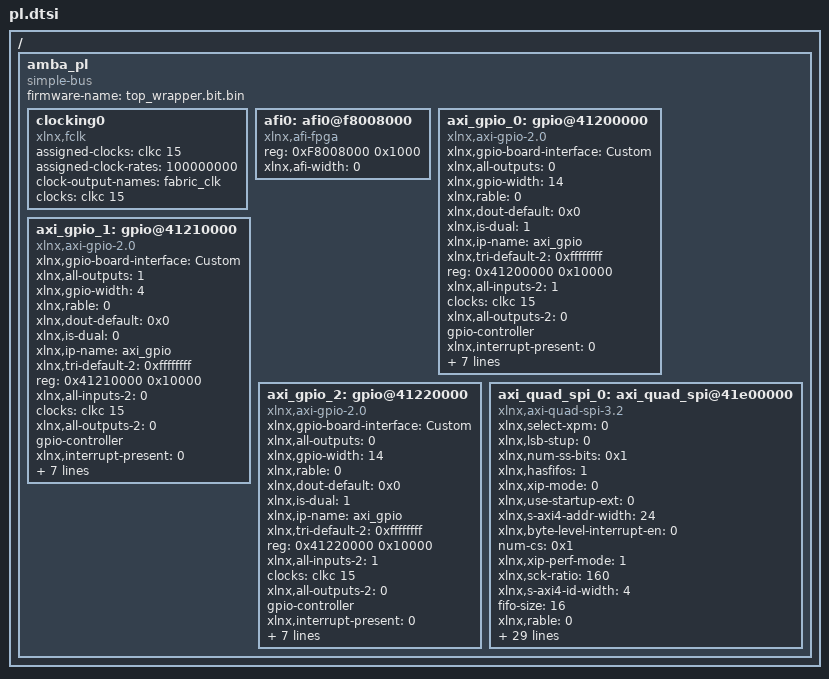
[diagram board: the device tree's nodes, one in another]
/ {
	amba_pl: amba_pl {
		ranges;
		compatible = "simple-bus";
		#address-cells = <1>;
		#size-cells = <1>;
		firmware-name = "top_wrapper.bit.bin";
		clocking0: clocking0 {
			compatible = "xlnx,fclk";
			assigned-clocks = <&clkc 15>;
			assigned-clock-rates = <100000000>;
			#clock-cells = <0>;
			clock-output-names = "fabric_clk";
			clocks = <&clkc 15>;
		};
		afi0: afi0@f8008000 {
			status = "okay";
			compatible = "xlnx,afi-fpga";
			#address-cells = <1>;
			reg = <0xF8008000 0x1000>;
			#size-cells = <0>;
			xlnx,afi-width = <0>;
		};
		axi_gpio_0: gpio@41200000 {
			xlnx,gpio-board-interface = "Custom";
			compatible = "xlnx,axi-gpio-2.0" , "xlnx,xps-gpio-1.00.a";
			xlnx,all-outputs = <0>;
			#gpio-cells = <2>;
			xlnx,gpio-width = <14>;
			xlnx,rable = <0>;
			xlnx,dout-default = <0x0>;
			xlnx,is-dual = <1>;
			xlnx,ip-name = "axi_gpio";
			xlnx,tri-default-2 = <0xffffffff>;
			reg = <0x41200000 0x10000>;
			xlnx,all-inputs-2 = <1>;
			clocks = <&clkc 15>;
			xlnx,all-outputs-2 = <0>;
			gpio-controller;
			xlnx,interrupt-present = <0>;
			xlnx,gpio2-board-interface = "Custom";
			xlnx,edk-iptype = "PERIPHERAL";
			xlnx,dout-default-2 = <0x0>;
			status = "okay";
			xlnx,gpio2-width = <14>;
			clock-names = "s_axi_aclk";
			xlnx,tri-default = <0xffffffff>;
			xlnx,name = "axi_gpio_0";
			xlnx,all-inputs = <1>;
		};
		axi_gpio_1: gpio@41210000 {
			xlnx,gpio-board-interface = "Custom";
			compatible = "xlnx,axi-gpio-2.0" , "xlnx,xps-gpio-1.00.a";
			xlnx,all-outputs = <1>;
			#gpio-cells = <2>;
			xlnx,gpio-width = <4>;
			xlnx,rable = <0>;
			xlnx,dout-default = <0x0>;
			xlnx,is-dual = <0>;
			xlnx,ip-name = "axi_gpio";
			xlnx,tri-default-2 = <0xffffffff>;
			reg = <0x41210000 0x10000>;
			xlnx,all-inputs-2 = <0>;
			clocks = <&clkc 15>;
			xlnx,all-outputs-2 = <0>;
			gpio-controller;
			xlnx,interrupt-present = <0>;
			xlnx,gpio2-board-interface = "Custom";
			xlnx,edk-iptype = "PERIPHERAL";
			xlnx,dout-default-2 = <0x0>;
			status = "okay";
			xlnx,gpio2-width = <32>;
			clock-names = "s_axi_aclk";
			xlnx,tri-default = <0xffffffff>;
			xlnx,name = "axi_gpio_1";
			xlnx,all-inputs = <0>;
		};
		axi_gpio_2: gpio@41220000 {
			xlnx,gpio-board-interface = "Custom";
			compatible = "xlnx,axi-gpio-2.0" , "xlnx,xps-gpio-1.00.a";
			xlnx,all-outputs = <0>;
			#gpio-cells = <2>;
			xlnx,gpio-width = <14>;
			xlnx,rable = <0>;
			xlnx,dout-default = <0x0>;
			xlnx,is-dual = <1>;
			xlnx,ip-name = "axi_gpio";
			xlnx,tri-default-2 = <0xffffffff>;
			reg = <0x41220000 0x10000>;
			xlnx,all-inputs-2 = <1>;
			clocks = <&clkc 15>;
			xlnx,all-outputs-2 = <0>;
			gpio-controller;
			xlnx,interrupt-present = <0>;
			xlnx,gpio2-board-interface = "Custom";
			xlnx,edk-iptype = "PERIPHERAL";
			xlnx,dout-default-2 = <0x0>;
			status = "okay";
			xlnx,gpio2-width = <14>;
			clock-names = "s_axi_aclk";
			xlnx,tri-default = <0xffffffff>;
			xlnx,name = "axi_gpio_2";
			xlnx,all-inputs = <1>;
		};
		axi_quad_spi_0: axi_quad_spi@41e00000 {
			xlnx,select-xpm = <0>;
			compatible = "xlnx,axi-quad-spi-3.2" , "xlnx,xps-spi-2.00.a";
			xlnx,lsb-stup = <0>;
			xlnx,num-ss-bits = <0x1>;
			xlnx,hasfifos = <1>;
			xlnx,xip-mode = <0>;
			xlnx,use-startup-ext = <0>;
			xlnx,s-axi4-addr-width = <24>;
			xlnx,byte-level-interrupt-en = <0>;
			num-cs = <0x1>;
			xlnx,xip-perf-mode = <1>;
			xlnx,sck-ratio = <160>;
			xlnx,s-axi4-id-width = <4>;
			fifo-size = <16>;
			xlnx,rable = <0>;
			xlnx,multiples16 = <10>;
			xlnx,master-mode = <1>;
			xlnx,shared-startup = <0>;
			xlnx,ip-name = "axi_quad_spi";
			xlnx,qspi-board-interface = "Custom";
			reg = <0x41e00000 0x10000>;
			xlnx,dual-quad-mode = <0>;
			xlnx,new-seq-en = <1>;
			bits-per-word = <8>;
			clocks = <&clkc 15>, <&clkc 15>;
			xlnx,num-transfer-bits = <8>;
			xlnx,spi-memory = <1>;
			xlnx,s-axi4-data-width = <32>;
			xlnx,edk-iptype = "PERIPHERAL";
			xlnx,slaveonly = <0>;
			xlnx,use-startup-int = <0>;
			xlnx,use-startup = <0>;
			xlnx,type-of-axi4-interface = <0>;
			xlnx,async-clk = <0>;
			xlnx,spi-mode = <0>;
			xlnx,sck-ratio1 = <1>;
			status = "okay";
			xlnx,fifo-depth = <16>;
			clock-names = "ext_spi_clk" , "s_axi_aclk";
			xlnx,uc-family = <0>;
			xlnx,spi-mem-addr-bits = <24>;
			xlnx,axi-interface = <0>;
			xlnx,Axi4-address = <0>;
			xlnx,fifo-included = <1>;
			xlnx,sub-family = "zynq";
			xlnx,name = "axi_quad_spi_0";
		};
	};
};
